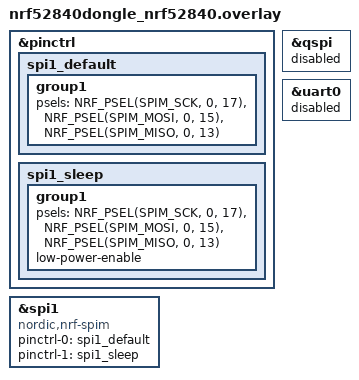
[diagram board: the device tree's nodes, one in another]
/*
 * Devicetree overlay for AD5940 on nRF52840 Dongle (PCA10059)
 *
 * Wiring:
 *   SCLK  -> P0.17
 *   MOSI  -> P0.15
 *   MISO  -> P0.13
 *   CS    -> P0.20  (GPIO, software-controlled)
 *   RESET -> P0.22  (GPIO, software-controlled)
 *   GP0   -> P0.24  (AD5940 interrupt output)
 */

&pinctrl {
    spi1_default: spi1_default {
        group1 {
            psels = <NRF_PSEL(SPIM_SCK,  0, 17)>,
                    <NRF_PSEL(SPIM_MOSI, 0, 15)>,
                    <NRF_PSEL(SPIM_MISO, 0, 13)>;
        };
    };

    spi1_sleep: spi1_sleep {
        group1 {
            psels = <NRF_PSEL(SPIM_SCK,  0, 17)>,
                    <NRF_PSEL(SPIM_MOSI, 0, 15)>,
                    <NRF_PSEL(SPIM_MISO, 0, 13)>;
            low-power-enable;
        };
    };
};

&spi1 {
    compatible = "nordic,nrf-spim";
    status = "okay";
    pinctrl-0 = <&spi1_default>;
    pinctrl-1 = <&spi1_sleep>;
    pinctrl-names = "default", "sleep";
};

&qspi {
    status = "disabled";
};
&uart0 {
    status = "disabled";
};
